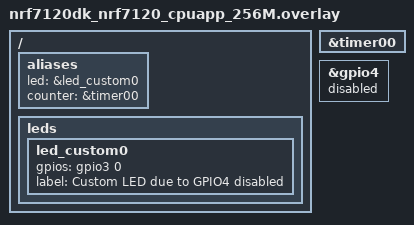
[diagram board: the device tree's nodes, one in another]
/*
 * Copyright (c) 2026 Nordic Semiconductor ASA
 *
 * SPDX-License-Identifier: LicenseRef-Nordic-5-Clause
 */

/* TIMER00, 256MHz */

/ {
	aliases {
		led = &led_custom0;
		counter = &timer00;
	};

	leds {
		led_custom0: led_custom0 {
			gpios = <&gpio3 0 GPIO_ACTIVE_HIGH>;
			label = "Custom LED due to GPIO4 disabled";
		};
	};
};

&timer00 {
	status = "okay";
};

&gpio4 {
	status = "disabled";
};
